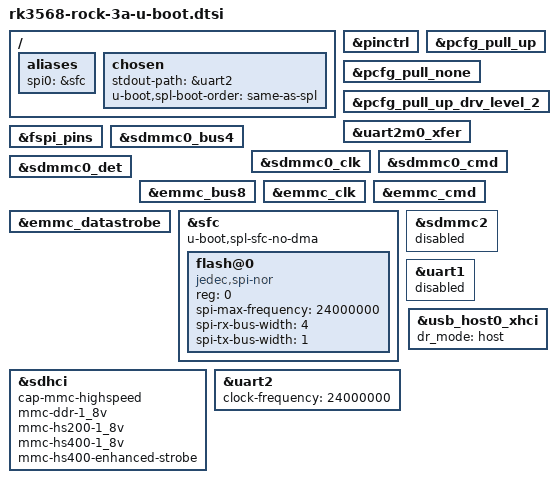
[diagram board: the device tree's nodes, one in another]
// SPDX-License-Identifier: GPL-2.0+
/*
 * (C) Copyright 2021 Rockchip Electronics Co., Ltd
 * (C) Copyright 2023 Akash Gajjar <gajjar04akash@gmail.com>
 */

#include "rk356x-u-boot.dtsi"

/ {
	aliases {
		spi0 = &sfc;
	};

	chosen {
		stdout-path = &uart2;
		u-boot,spl-boot-order = "same-as-spl", &sdmmc0, &sdhci;
	};
};

&pinctrl {
	bootph-pre-ram;
};

&pcfg_pull_up {
	bootph-pre-ram;
};

&pcfg_pull_none {
	bootph-pre-ram;
};

&pcfg_pull_up_drv_level_2 {
	bootph-pre-ram;
};

&uart2m0_xfer {
	bootph-pre-ram;
};

&fspi_pins {
	bootph-pre-ram;
};

&sdmmc0_bus4 {
	bootph-pre-ram;
};

&sdmmc0_clk {
	bootph-pre-ram;
};

&sdmmc0_cmd {
	bootph-pre-ram;
};

&sdmmc0_det {
	bootph-pre-ram;
};

&emmc_bus8 {
	bootph-pre-ram;
};

&emmc_clk {
	bootph-pre-ram;
};

&emmc_cmd {
	bootph-pre-ram;
};

&emmc_datastrobe {
	bootph-pre-ram;
};

&sfc {
	bootph-pre-ram;
	u-boot,spl-sfc-no-dma;
	#address-cells = <1>;
	#size-cells = <0>;
	status = "okay";

	flash@0 {
		bootph-pre-ram;
		compatible = "jedec,spi-nor";
		reg = <0>;
		spi-max-frequency = <24000000>;
		spi-rx-bus-width = <4>;
		spi-tx-bus-width = <1>;
	};
};

&sdhci {
	cap-mmc-highspeed;
	mmc-ddr-1_8v;
	mmc-hs200-1_8v;
	mmc-hs400-1_8v;
	mmc-hs400-enhanced-strobe;
};

&sdmmc2 {
	status = "disabled";
};

&uart1 {
	status = "disabled";
};

&uart2 {
	clock-frequency = <24000000>;
	bootph-all;
	status = "okay";
};

&usb_host0_xhci {
	dr_mode = "host";
};
